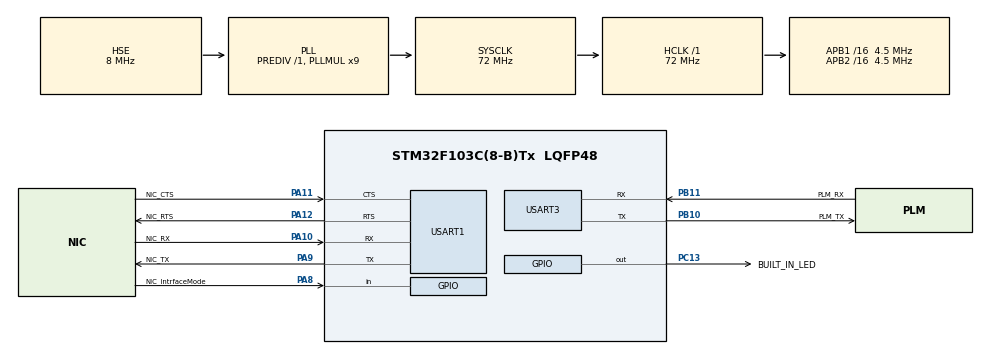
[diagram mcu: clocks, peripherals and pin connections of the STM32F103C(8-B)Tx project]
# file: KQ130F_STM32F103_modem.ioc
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FREERTOS.Tasks01=defaultTask,24,128,StartDefaultTask,Default,NULL,Dynamic,NULL,NULL
FREERTOS.configUSE_NEWLIB_REENTRANT=1
FREERTOS.configUSE_PREEMPTION=0
Mcu.Family=STM32F1
Mcu.Name=STM32F103C(8-B)Tx
Mcu.Package=LQFP48
NVIC.PriorityGroup=NVIC_PRIORITYGROUP_4
NVIC.TIM1_UP_IRQn=true\:15\:0\:false\:false\:true\:false\:false\:true\:true
NVIC.TimeBase=TIM1_UP_IRQn
NVIC.TimeBaseIP=TIM1
PA10.GPIO_Label=NIC_RX
PA10.Mode=Asynchronous
PA10.Signal=USART1_RX
PA11.GPIO_Label=NIC_CTS
PA11.Mode=CTS_RTS
PA11.Signal=USART1_CTS
PA12.GPIO_Label=NIC_RTS
PA12.Mode=CTS_RTS
PA12.Signal=USART1_RTS
PA8.GPIO_Label=NIC_IntrfaceMode
PA8.Signal=GPIO_Input
PA9.GPIO_Label=NIC_TX
PA9.Mode=Asynchronous
PA9.Signal=USART1_TX
PB10.GPIO_Label=PLM_TX
PB10.Mode=Asynchronous
PB10.Signal=USART3_TX
PB11.GPIO_Label=PLM_RX
PB11.Mode=Asynchronous
PB11.Signal=USART3_RX
PC13-TAMPER-RTC.GPIO_Label=BUILT_IN_LED
PC13-TAMPER-RTC.Signal=GPIO_Output
PC14-OSC32_IN.Mode=LSE-External-Oscillator
PC14-OSC32_IN.Signal=RCC_OSC32_IN
PC15-OSC32_OUT.Mode=LSE-External-Oscillator
PC15-OSC32_OUT.Signal=RCC_OSC32_OUT
PD0-OSC_IN.Mode=HSE-External-Oscillator
PD0-OSC_IN.Signal=RCC_OSC_IN
PD1-OSC_OUT.Mode=HSE-External-Oscillator
PD1-OSC_OUT.Signal=RCC_OSC_OUT
ProjectManager.HeapSize=0x200
ProjectManager.StackSize=0x400
ProjectManager.TargetToolchain=STM32CubeIDE
RCC.AHBFreq_Value=72000000
RCC.APB1CLKDivider=RCC_HCLK_DIV16
RCC.APB1Freq_Value=4500000
RCC.APB1TimFreq_Value=9000000
RCC.APB2CLKDivider=RCC_HCLK_DIV16
RCC.APB2Freq_Value=4500000
RCC.APB2TimFreq_Value=9000000
RCC.EnbaleCSS=true
RCC.HCLKFreq_Value=72000000
RCC.PLLMUL=RCC_PLL_MUL9
RCC.PLLSourceVirtual=RCC_PLLSOURCE_HSE
RCC.SYSCLKFreq_VALUE=72000000
RCC.SYSCLKSource=RCC_SYSCLKSOURCE_PLLCLK
RCC.USBFreq_Value=72000000
RTC.OutPut=RTC_OUTPUTSOURCE_SECOND
USART1.VirtualMode=VM_ASYNC
USART3.VirtualMode=VM_ASYNC
VP_CRC_VS_CRC.Mode=CRC_Activate
VP_FREERTOS_VS_CMSIS_V2.Mode=CMSIS_V2
VP_RTC_VS_RTC_Activate.Mode=RTC_Enabled
VP_RTC_VS_RTC_Calendar.Mode=RTC_Calendar
VP_SYS_VS_ND.Mode=No_Debug
VP_SYS_VS_tim1.Mode=TIM1
board=custom

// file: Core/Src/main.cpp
/* USER CODE BEGIN Header */
/**
  ******************************************************************************
  * @file           : main.c
  * @brief          : Main program body
  ******************************************************************************
  * @attention
  *
  * Copyright (c) 2022 STMicroelectronics.
  * All rights reserved.
  *
  * This software is licensed under terms that can be found in the LICENSE file
  * in the root directory of this software component.
  * If no LICENSE file comes with this software, it is provided AS-IS.
  *
  ******************************************************************************
  */
/* USER CODE END Header */
#include "main.h"
#include "cmsis_os.h"
#include "initializer_list"

 CRC_HandleTypeDef hcrc;

RTC_HandleTypeDef hrtc;

UART_HandleTypeDef huart1;
UART_HandleTypeDef huart3;

/* Definitions for defaultTask */
osThreadId_t defaultTaskHandle;
const osThreadAttr_t defaultTask_attributes = {
  .name = "defaultTask",
  .stack_size = 128 * 4,
  .priority = (osPriority_t) osPriorityNormal,
};

void SystemClock_Config(void);
static void MX_GPIO_Init(void);
static void MX_CRC_Init(void);
static void MX_USART1_UART_Init(void);
static void MX_USART3_UART_Init(void);
static void MX_RTC_Init(void);
void StartDefaultTask(void *argument);

/* USER CODE BEGIN PFP */
void ledFunc(void* arg);
/* USER CODE END PFP */

/* USER CODE BEGIN 0 */
void ledFunc(void* arg) {
	HAL_GPIO_TogglePin(BUILT_IN_LED_GPIO_Port, BUILT_IN_LED_Pin);
	osDelayUntil(pdMS_TO_TICKS(500));
}
/* USER CODE END 0 */

int main(void)
{

  /* MCU Configuration--------------------------------------------------------*/

  /* Reset of all peripherals, Initializes the Flash interface and the Systick. */
  HAL_Init();

  /* Configure the system clock */
  SystemClock_Config();

  /* Initialize all configured peripherals */
  MX_GPIO_Init();
  MX_CRC_Init();
  MX_USART1_UART_Init();
  MX_USART3_UART_Init();
  MX_RTC_Init();

  /* Init scheduler */
  osKernelInitialize();

  /* Create the thread(s) */
  /* creation of defaultTask */
  defaultTaskHandle = osThreadNew(StartDefaultTask, NULL, &defaultTask_attributes);
  osThreadAttr_t properties = { .name = "ledBlinkTask", .stack_size = 128, .priority = (osPriority_t) osPriorityNormal};
  osThreadNew(ledFunc, NULL, &properties);

  /* Start scheduler */
  osKernelStart();

  /* We should never get here as control is now taken by the scheduler */
  /* Infinite loop */
  while (1)
  {

  }
}

void SystemClock_Config(void)
{
  RCC_OscInitTypeDef RCC_OscInitStruct = {0};
  RCC_ClkInitTypeDef RCC_ClkInitStruct = {0};
  RCC_PeriphCLKInitTypeDef PeriphClkInit = {0};

  /** Initializes the RCC Oscillators according to the specified parameters
  * in the RCC_OscInitTypeDef structure.
  */
  RCC_OscInitStruct.OscillatorType = RCC_OSCILLATORTYPE_LSI|RCC_OSCILLATORTYPE_HSE;
  RCC_OscInitStruct.HSEState = RCC_HSE_ON;
  RCC_OscInitStruct.HSEPredivValue = RCC_HSE_PREDIV_DIV1;
  RCC_OscInitStruct.HSIState = RCC_HSI_ON;
  RCC_OscInitStruct.LSIState = RCC_LSI_ON;
  RCC_OscInitStruct.PLL.PLLState = RCC_PLL_ON;
  RCC_OscInitStruct.PLL.PLLSource = RCC_PLLSOURCE_HSE;
  RCC_OscInitStruct.PLL.PLLMUL = RCC_PLL_MUL9;
  if (HAL_RCC_OscConfig(&RCC_OscInitStruct) != HAL_OK)
  {
    Error_Handler();
  }

  /** Initializes the CPU, AHB and APB buses clocks
  */
  RCC_ClkInitStruct.ClockType = RCC_CLOCKTYPE_HCLK|RCC_CLOCKTYPE_SYSCLK
                              |RCC_CLOCKTYPE_PCLK1|RCC_CLOCKTYPE_PCLK2;
  RCC_ClkInitStruct.SYSCLKSource = RCC_SYSCLKSOURCE_PLLCLK;
  RCC_ClkInitStruct.AHBCLKDivider = RCC_SYSCLK_DIV1;
  RCC_ClkInitStruct.APB1CLKDivider = RCC_HCLK_DIV16;
  RCC_ClkInitStruct.APB2CLKDivider = RCC_HCLK_DIV16;

  if (HAL_RCC_ClockConfig(&RCC_ClkInitStruct, FLASH_LATENCY_2) != HAL_OK)
  {
    Error_Handler();
  }
  PeriphClkInit.PeriphClockSelection = RCC_PERIPHCLK_RTC;
  PeriphClkInit.RTCClockSelection = RCC_RTCCLKSOURCE_LSI;
  if (HAL_RCCEx_PeriphCLKConfig(&PeriphClkInit) != HAL_OK)
  {
    Error_Handler();
  }

  /** Enables the Clock Security System
  */
  HAL_RCC_EnableCSS();
}

static void MX_CRC_Init(void)
{

  hcrc.Instance = CRC;
  if (HAL_CRC_Init(&hcrc) != HAL_OK)
  {
    Error_Handler();
  }

}

static void MX_RTC_Init(void)
{

  RTC_TimeTypeDef sTime = {0};
  RTC_DateTypeDef DateToUpdate = {0};

  /** Initialize RTC Only
  */
  hrtc.Instance = RTC;
  hrtc.Init.AsynchPrediv = RTC_AUTO_1_SECOND;
  hrtc.Init.OutPut = RTC_OUTPUTSOURCE_SECOND;
  if (HAL_RTC_Init(&hrtc) != HAL_OK)
  {
    Error_Handler();
  }

  /** Initialize RTC and set the Time and Date
  */
  sTime.Hours = 0x0;
  sTime.Minutes = 0x0;
  sTime.Seconds = 0x0;

  if (HAL_RTC_SetTime(&hrtc, &sTime, RTC_FORMAT_BCD) != HAL_OK)
  {
    Error_Handler();
  }
  DateToUpdate.WeekDay = RTC_WEEKDAY_MONDAY;
  DateToUpdate.Month = RTC_MONTH_JANUARY;
  DateToUpdate.Date = 0x1;
  DateToUpdate.Year = 0x0;

  if (HAL_RTC_SetDate(&hrtc, &DateToUpdate, RTC_FORMAT_BCD) != HAL_OK)
  {
    Error_Handler();
  }

}

static void MX_USART1_UART_Init(void)
{

  huart1.Instance = USART1;
  huart1.Init.BaudRate = 115200;
  huart1.Init.WordLength = UART_WORDLENGTH_8B;
  huart1.Init.StopBits = UART_STOPBITS_1;
  huart1.Init.Parity = UART_PARITY_NONE;
  huart1.Init.Mode = UART_MODE_TX_RX;
  huart1.Init.HwFlowCtl = UART_HWCONTROL_RTS_CTS;
  huart1.Init.OverSampling = UART_OVERSAMPLING_16;
  if (HAL_UART_Init(&huart1) != HAL_OK)
  {
    Error_Handler();
  }

}

static void MX_USART3_UART_Init(void)
{

  huart3.Instance = USART3;
  huart3.Init.BaudRate = 115200;
  huart3.Init.WordLength = UART_WORDLENGTH_8B;
  huart3.Init.StopBits = UART_STOPBITS_1;
  huart3.Init.Parity = UART_PARITY_NONE;
  huart3.Init.Mode = UART_MODE_TX_RX;
  huart3.Init.HwFlowCtl = UART_HWCONTROL_NONE;
  huart3.Init.OverSampling = UART_OVERSAMPLING_16;
  if (HAL_UART_Init(&huart3) != HAL_OK)
  {
    Error_Handler();
  }

}

static void MX_GPIO_Init(void)
{
  GPIO_InitTypeDef GPIO_InitStruct = {0};

  /* GPIO Ports Clock Enable */
  __HAL_RCC_GPIOC_CLK_ENABLE();
  __HAL_RCC_GPIOD_CLK_ENABLE();
  __HAL_RCC_GPIOB_CLK_ENABLE();
  __HAL_RCC_GPIOA_CLK_ENABLE();

  /*Configure GPIO pin Output Level */
  HAL_GPIO_WritePin(BUILT_IN_LED_GPIO_Port, BUILT_IN_LED_Pin, GPIO_PIN_RESET);

  /*Configure GPIO pin : BUILT_IN_LED_Pin */
  GPIO_InitStruct.Pin = BUILT_IN_LED_Pin;
  GPIO_InitStruct.Mode = GPIO_MODE_OUTPUT_PP;
  GPIO_InitStruct.Pull = GPIO_NOPULL;
  GPIO_InitStruct.Speed = GPIO_SPEED_FREQ_LOW;
  HAL_GPIO_Init(BUILT_IN_LED_GPIO_Port, &GPIO_InitStruct);

  /*Configure GPIO pin : NIC_IntrfaceMode_Pin */
  GPIO_InitStruct.Pin = NIC_IntrfaceMode_Pin;
  GPIO_InitStruct.Mode = GPIO_MODE_INPUT;
  GPIO_InitStruct.Pull = GPIO_NOPULL;
  HAL_GPIO_Init(NIC_IntrfaceMode_GPIO_Port, &GPIO_InitStruct);

}

void StartDefaultTask(void *argument)
{
  for(;;)
  {
    osDelay(1);
  }
}

void HAL_TIM_PeriodElapsedCallback(TIM_HandleTypeDef *htim)
{
  if (htim->Instance == TIM1) {
    HAL_IncTick();
  }
}

void Error_Handler(void)
{
  __disable_irq();
  while (1)
  {
  }
}
